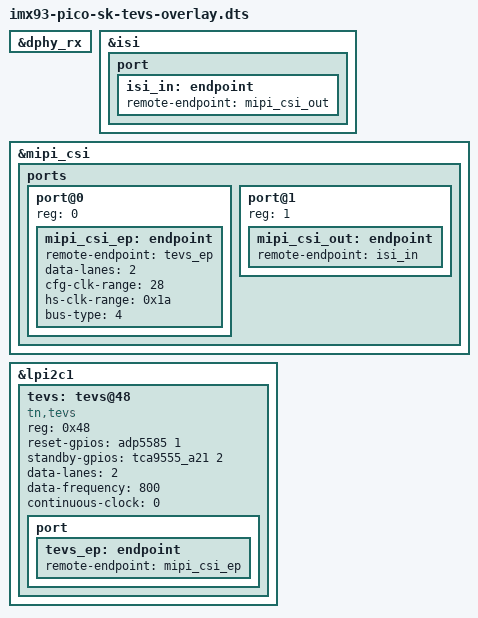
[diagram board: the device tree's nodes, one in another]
// SPDX-License-Identifier: (GPL-2.0 OR MIT)
/*
 * Copyright 2024 TechNexion Ltd.
 *
 * Author: Nian Yang <nian.yang@technexion.com>
 *
 */

/dts-v1/;
/plugin/;

#include <dt-bindings/interrupt-controller/irq.h>
#include <dt-bindings/clock/imx8mm-clock.h>
#include <dt-bindings/gpio/gpio.h>

/ {
	fragment@0 {
		target = <&dphy_rx>;
		__overlay__ {
			status = "okay";
		};
	};

	fragment@1 {
		target = <&isi>;
		__overlay__ {
			status = "okay";

			port {
				isi_in: endpoint {
					remote-endpoint = <&mipi_csi_out>;
				};
			};
		};
	};

	fragment@2 {
		target = <&mipi_csi>;
		__overlay__ {
			#address-cells = <1>;
			#size-cells = <0>;
			status = "okay";

			ports {
				#address-cells = <1>;
				#size-cells = <0>;

				port@0 {
					reg = <0>;
					mipi_csi_ep: endpoint {
						remote-endpoint = <&tevs_ep>;
						data-lanes = <2>;
						cfg-clk-range = <28>;
						hs-clk-range = <0x1a>;
						bus-type = <4>;
					};
				};

				port@1 {
					reg = <1>;

					mipi_csi_out: endpoint {
						remote-endpoint = <&isi_in>;
					};
				};
			};
		};
	};

	fragment@3 {
		target = <&lpi2c1>;
		__overlay__ {
			#address-cells = <1>;
			#size-cells = <0>;
			status = "okay";

			tevs: tevs@48 {
				compatible = "tn,tevs";
				reg = <0x48>;

				reset-gpios = <&adp5585 1 GPIO_ACTIVE_HIGH>;
				standby-gpios = <&tca9555_a21 2 GPIO_ACTIVE_HIGH>;

				data-lanes = <2>;
				data-frequency = <800>;
				continuous-clock = <0>;
				status = "okay";

				port {
					tevs_ep: endpoint {
						remote-endpoint = <&mipi_csi_ep>;
					};
				};
			};
		};
	};
};
